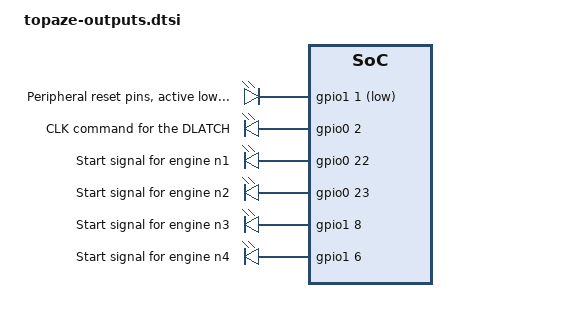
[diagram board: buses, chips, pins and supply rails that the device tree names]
/* ============================================================
 * This file is the overlay DTS for topaze that define the GPIOs
 *
 * We describe here the peripherals configuration for the outputs 
 * only.
 *
 * l.heywang
 * 01/03/2025
 *
 * ============================================================
 */

// ============================================================
// GPIO OUTPUTS CONTROL
// ============================================================
&pinctrl {
    outputs {
		compatible = "gpio-leds";

        peripheralreset: peripheralreset {
            gpios =     <&gpio1 1 GPIO_ACTIVE_LOW>;
            label =     "Peripheral reset pins, active low...";
        };

        latch: latch {
            gpios =     <&gpio0 2 GPIO_ACTIVE_HIGH>;
            label =     "CLK command for the DLATCH";
        };

        engine1: engine1{
            gpios =     <&gpio0 22 GPIO_ACTIVE_HIGH>;
            label =     "Start signal for engine n1";
        };

        engine2: engine2{
            gpios =     <&gpio0 23 GPIO_ACTIVE_HIGH>;
            label =     "Start signal for engine n2";
        };

        engine3: engine3{
            gpios =     <&gpio1 8 GPIO_ACTIVE_HIGH>;
            label =     "Start signal for engine n3";
        };

        engine4: engine4{
            gpios =     <&gpio1 6 GPIO_ACTIVE_HIGH>;
            label =     "Start signal for engine n4";
        };
	};
};

/{
    aliases {
        peripheralreset = &peripheralreset;
        latch = &latch;
        engine1 = &engine1;
        engine2 = &engine2;
        engine3 = &engine3;
        engine4 = &engine4;
    };
};


